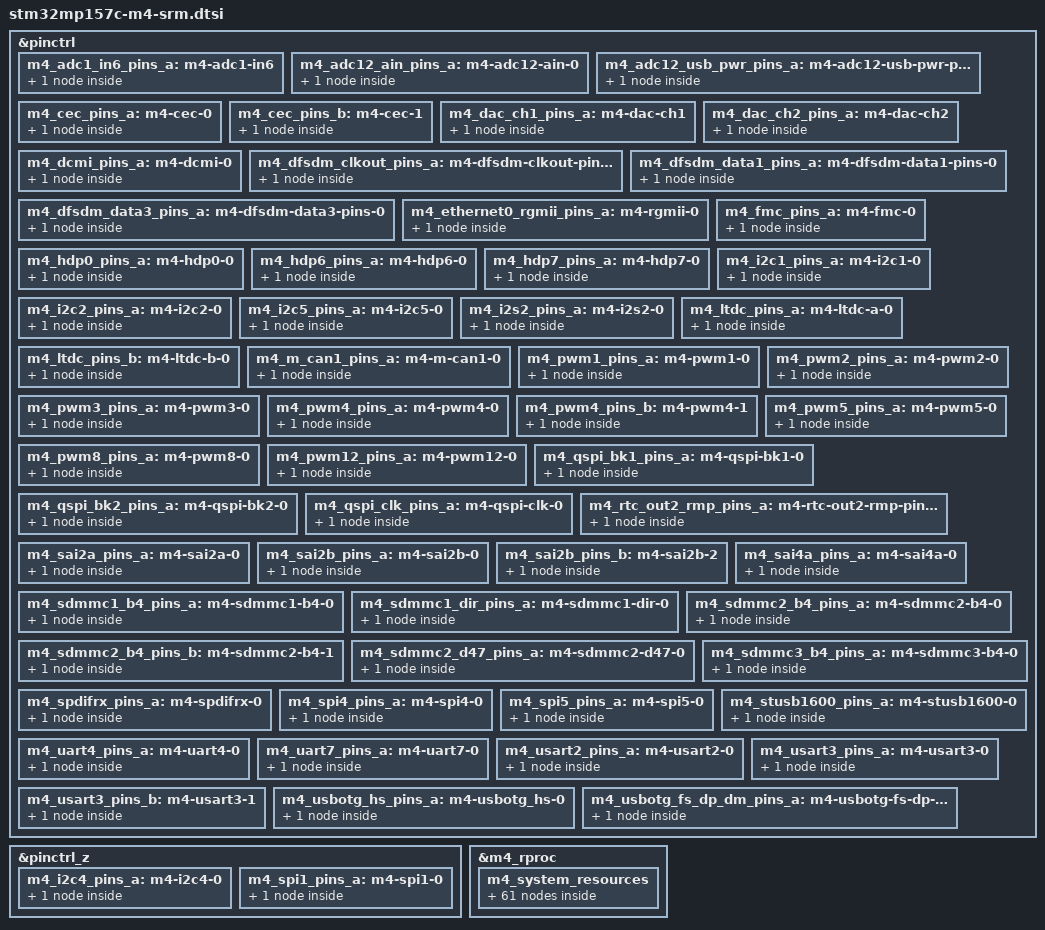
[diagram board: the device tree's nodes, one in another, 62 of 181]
// SPDX-License-Identifier: (GPL-2.0+ OR BSD-3-Clause)
/*
 * Copyright (C) STMicroelectronics 2019 - All Rights Reserved
 * Author: Fabien Dessenne <fabien.dessenne@st.com> for STMicroelectronics.
 */

&pinctrl {
	m4_adc1_in6_pins_a: m4-adc1-in6 {
		pins {
			pinmux = <STM32_PINMUX('F', 12, RSVD)>;
		};
	};

	m4_adc12_ain_pins_a: m4-adc12-ain-0 {
		pins {
			pinmux = <STM32_PINMUX('C', 3, RSVD)>, /* ADC1 in13 */
				 <STM32_PINMUX('F', 12, RSVD)>, /* ADC1 in6 */
				 <STM32_PINMUX('F', 13, RSVD)>, /* ADC2 in2 */
				 <STM32_PINMUX('F', 14, RSVD)>; /* ADC2 in6 */
		};
	};

	m4_adc12_usb_pwr_pins_a: m4-adc12-usb-pwr-pins-0 {
		pins {
			pinmux = <STM32_PINMUX('A', 4, RSVD)>, /* ADC12 in18 */
				 <STM32_PINMUX('A', 5, RSVD)>; /* ADC12 in19 */
		};
	};

	m4_cec_pins_a: m4-cec-0 {
		pins {
			pinmux = <STM32_PINMUX('A', 15, RSVD)>;
		};
	};

	m4_cec_pins_b: m4-cec-1 {
		pins {
			pinmux = <STM32_PINMUX('B', 6, RSVD)>;
		};
	};

	m4_dac_ch1_pins_a: m4-dac-ch1 {
		pins {
			pinmux = <STM32_PINMUX('A', 4, RSVD)>;
		};
	};

	m4_dac_ch2_pins_a: m4-dac-ch2 {
		pins {
			pinmux = <STM32_PINMUX('A', 5, RSVD)>;
		};
	};

	m4_dcmi_pins_a: m4-dcmi-0 {
		pins {
			pinmux = <STM32_PINMUX('H', 8,  RSVD)>,/* DCMI_HSYNC */
				 <STM32_PINMUX('B', 7,  RSVD)>,/* DCMI_VSYNC */
				 <STM32_PINMUX('A', 6,  RSVD)>,/* DCMI_PIXCLK */
				 <STM32_PINMUX('H', 9,  RSVD)>,/* DCMI_D0 */
				 <STM32_PINMUX('H', 10, RSVD)>,/* DCMI_D1 */
				 <STM32_PINMUX('H', 11, RSVD)>,/* DCMI_D2 */
				 <STM32_PINMUX('H', 12, RSVD)>,/* DCMI_D3 */
				 <STM32_PINMUX('H', 14, RSVD)>,/* DCMI_D4 */
				 <STM32_PINMUX('I', 4,  RSVD)>,/* DCMI_D5 */
				 <STM32_PINMUX('B', 8,  RSVD)>,/* DCMI_D6 */
				 <STM32_PINMUX('E', 6,  RSVD)>,/* DCMI_D7 */
				 <STM32_PINMUX('I', 1,  RSVD)>,/* DCMI_D8 */
				 <STM32_PINMUX('H', 7,  RSVD)>,/* DCMI_D9 */
				 <STM32_PINMUX('I', 3,  RSVD)>,/* DCMI_D10 */
				 <STM32_PINMUX('H', 15, RSVD)>;/* DCMI_D11 */
		};
	};

	m4_dfsdm_clkout_pins_a: m4-dfsdm-clkout-pins-0 {
		pins {
			pinmux = <STM32_PINMUX('B', 13, RSVD)>; /* DFSDM_CKOUT */
		};
	};

	m4_dfsdm_data1_pins_a: m4-dfsdm-data1-pins-0 {
		pins {
			pinmux = <STM32_PINMUX('C', 3, RSVD)>; /* DFSDM_DATA1 */
		};
	};

	m4_dfsdm_data3_pins_a: m4-dfsdm-data3-pins-0 {
		pins {
			pinmux = <STM32_PINMUX('F', 13, RSVD)>; /* DFSDM_DATA3 */
		};
	};

	m4_ethernet0_rgmii_pins_a: m4-rgmii-0 {
		pins {
			pinmux = <STM32_PINMUX('G', 5, RSVD)>, /* ETH_RGMII_CLK125 */
				 <STM32_PINMUX('G', 4, RSVD)>, /* ETH_RGMII_GTX_CLK */
				 <STM32_PINMUX('G', 13, RSVD)>, /* ETH_RGMII_TXD0 */
				 <STM32_PINMUX('G', 14, RSVD)>, /* ETH_RGMII_TXD1 */
				 <STM32_PINMUX('C', 2, RSVD)>, /* ETH_RGMII_TXD2 */
				 <STM32_PINMUX('E', 2, RSVD)>, /* ETH_RGMII_TXD3 */
				 <STM32_PINMUX('B', 11, RSVD)>, /* ETH_RGMII_TX_CTL */
				 <STM32_PINMUX('C', 1, RSVD)>, /* ETH_MDC */
				 <STM32_PINMUX('A', 2, RSVD)>, /* ETH_MDIO */
				 <STM32_PINMUX('C', 4, RSVD)>, /* ETH_RGMII_RXD0 */
				 <STM32_PINMUX('C', 5, RSVD)>, /* ETH_RGMII_RXD1 */
				 <STM32_PINMUX('B', 0, RSVD)>, /* ETH_RGMII_RXD2 */
				 <STM32_PINMUX('B', 1, RSVD)>, /* ETH_RGMII_RXD3 */
				 <STM32_PINMUX('A', 1, RSVD)>, /* ETH_RGMII_RX_CLK */
				 <STM32_PINMUX('A', 7, RSVD)>; /* ETH_RGMII_RX_CTL */
		};
	};

	m4_fmc_pins_a: m4-fmc-0 {
		pins {
			pinmux = <STM32_PINMUX('D', 4, RSVD)>, /* FMC_NOE */
				 <STM32_PINMUX('D', 5, RSVD)>, /* FMC_NWE */
				 <STM32_PINMUX('D', 11, RSVD)>, /* FMC_A16_FMC_CLE */
				 <STM32_PINMUX('D', 12, RSVD)>, /* FMC_A17_FMC_ALE */
				 <STM32_PINMUX('D', 14, RSVD)>, /* FMC_D0 */
				 <STM32_PINMUX('D', 15, RSVD)>, /* FMC_D1 */
				 <STM32_PINMUX('D', 0, RSVD)>, /* FMC_D2 */
				 <STM32_PINMUX('D', 1, RSVD)>, /* FMC_D3 */
				 <STM32_PINMUX('E', 7, RSVD)>, /* FMC_D4 */
				 <STM32_PINMUX('E', 8, RSVD)>, /* FMC_D5 */
				 <STM32_PINMUX('E', 9, RSVD)>, /* FMC_D6 */
				 <STM32_PINMUX('E', 10, RSVD)>, /* FMC_D7 */
				 <STM32_PINMUX('G', 9, RSVD)>, /* FMC_NE2_FMC_NCE */
				 <STM32_PINMUX('D', 6, RSVD)>; /* FMC_NWAIT */
		};
	};

	m4_hdp0_pins_a: m4-hdp0-0 {
		pins {
			pinmux = <STM32_PINMUX('I', 12, RSVD)>; /* HDP0 */
		};
	};

	m4_hdp6_pins_a: m4-hdp6-0 {
		pins {
			pinmux = <STM32_PINMUX('K', 5, RSVD)>; /* HDP6 */
		};
	};

	m4_hdp7_pins_a: m4-hdp7-0 {
		pins {
			pinmux = <STM32_PINMUX('K', 6, RSVD)>; /* HDP7 */
		};
	};

	m4_i2c1_pins_a: m4-i2c1-0 {
		pins {
			pinmux = <STM32_PINMUX('D', 12, RSVD)>, /* I2C1_SCL */
				 <STM32_PINMUX('F', 15, RSVD)>; /* I2C1_SDA */
		};
	};

	m4_i2c2_pins_a: m4-i2c2-0 {
		pins {
			pinmux = <STM32_PINMUX('H', 4, RSVD)>, /* I2C2_SCL */
				 <STM32_PINMUX('H', 5, RSVD)>; /* I2C2_SDA */
		};
	};

	m4_i2c5_pins_a: m4-i2c5-0 {
		pins {
			pinmux = <STM32_PINMUX('A', 11, RSVD)>, /* I2C5_SCL */
				 <STM32_PINMUX('A', 12, RSVD)>; /* I2C5_SDA */
		};
	};

	m4_i2s2_pins_a: m4-i2s2-0 {
		pins {
			pinmux = <STM32_PINMUX('I', 3, RSVD)>, /* I2S2_SDO */
				 <STM32_PINMUX('B', 9, RSVD)>, /* I2S2_WS */
				 <STM32_PINMUX('A', 9, RSVD)>; /* I2S2_CK */
		};
	};

	m4_ltdc_pins_a: m4-ltdc-a-0 {
		pins {
			pinmux = <STM32_PINMUX('G',  7, RSVD)>, /* LCD_CLK */
				 <STM32_PINMUX('I', 10, RSVD)>, /* LCD_HSYNC */
				 <STM32_PINMUX('I',  9, RSVD)>, /* LCD_VSYNC */
				 <STM32_PINMUX('F', 10, RSVD)>, /* LCD_DE */
				 <STM32_PINMUX('H',  2, RSVD)>, /* LCD_R0 */
				 <STM32_PINMUX('H',  3, RSVD)>, /* LCD_R1 */
				 <STM32_PINMUX('H',  8, RSVD)>, /* LCD_R2 */
				 <STM32_PINMUX('H',  9, RSVD)>, /* LCD_R3 */
				 <STM32_PINMUX('H', 10, RSVD)>, /* LCD_R4 */
				 <STM32_PINMUX('C',  0, RSVD)>, /* LCD_R5 */
				 <STM32_PINMUX('H', 12, RSVD)>, /* LCD_R6 */
				 <STM32_PINMUX('E', 15, RSVD)>, /* LCD_R7 */
				 <STM32_PINMUX('E',  5, RSVD)>, /* LCD_G0 */
				 <STM32_PINMUX('E',  6, RSVD)>, /* LCD_G1 */
				 <STM32_PINMUX('H', 13, RSVD)>, /* LCD_G2 */
				 <STM32_PINMUX('H', 14, RSVD)>, /* LCD_G3 */
				 <STM32_PINMUX('H', 15, RSVD)>, /* LCD_G4 */
				 <STM32_PINMUX('I',  0, RSVD)>, /* LCD_G5 */
				 <STM32_PINMUX('I',  1, RSVD)>, /* LCD_G6 */
				 <STM32_PINMUX('I',  2, RSVD)>, /* LCD_G7 */
				 <STM32_PINMUX('D',  9, RSVD)>, /* LCD_B0 */
				 <STM32_PINMUX('G', 12, RSVD)>, /* LCD_B1 */
				 <STM32_PINMUX('G', 10, RSVD)>, /* LCD_B2 */
				 <STM32_PINMUX('D', 10, RSVD)>, /* LCD_B3 */
				 <STM32_PINMUX('I',  4, RSVD)>, /* LCD_B4 */
				 <STM32_PINMUX('A',  3, RSVD)>, /* LCD_B5 */
				 <STM32_PINMUX('B',  8, RSVD)>, /* LCD_B6 */
				 <STM32_PINMUX('D',  8, RSVD)>; /* LCD_B7 */
		};
	};

	m4_ltdc_pins_b: m4-ltdc-b-0 {
		pins {
			pinmux = <STM32_PINMUX('I', 14, RSVD)>, /* LCD_CLK */
				 <STM32_PINMUX('I', 12, RSVD)>, /* LCD_HSYNC */
				 <STM32_PINMUX('I', 13, RSVD)>, /* LCD_VSYNC */
				 <STM32_PINMUX('K',  7, RSVD)>, /* LCD_DE */
				 <STM32_PINMUX('I', 15, RSVD)>, /* LCD_R0 */
				 <STM32_PINMUX('J',  0, RSVD)>, /* LCD_R1 */
				 <STM32_PINMUX('J',  1, RSVD)>, /* LCD_R2 */
				 <STM32_PINMUX('J',  2, RSVD)>, /* LCD_R3 */
				 <STM32_PINMUX('J',  3, RSVD)>, /* LCD_R4 */
				 <STM32_PINMUX('J',  4, RSVD)>, /* LCD_R5 */
				 <STM32_PINMUX('J',  5, RSVD)>, /* LCD_R6 */
				 <STM32_PINMUX('J',  6, RSVD)>, /* LCD_R7 */
				 <STM32_PINMUX('J',  7, RSVD)>, /* LCD_G0 */
				 <STM32_PINMUX('J',  8, RSVD)>, /* LCD_G1 */
				 <STM32_PINMUX('J',  9, RSVD)>, /* LCD_G2 */
				 <STM32_PINMUX('J', 10, RSVD)>, /* LCD_G3 */
				 <STM32_PINMUX('J', 11, RSVD)>, /* LCD_G4 */
				 <STM32_PINMUX('K',  0, RSVD)>, /* LCD_G5 */
				 <STM32_PINMUX('K',  1, RSVD)>, /* LCD_G6 */
				 <STM32_PINMUX('K',  2, RSVD)>, /* LCD_G7 */
				 <STM32_PINMUX('J', 12, RSVD)>, /* LCD_B0 */
				 <STM32_PINMUX('J', 13, RSVD)>, /* LCD_B1 */
				 <STM32_PINMUX('J', 14, RSVD)>, /* LCD_B2 */
				 <STM32_PINMUX('J', 15, RSVD)>, /* LCD_B3 */
				 <STM32_PINMUX('K',  3, RSVD)>, /* LCD_B4 */
				 <STM32_PINMUX('K',  4, RSVD)>, /* LCD_B5 */
				 <STM32_PINMUX('K',  5, RSVD)>, /* LCD_B6 */
				 <STM32_PINMUX('K',  6, RSVD)>; /* LCD_B7 */
		};
	};

	m4_m_can1_pins_a: m4-m-can1-0 {
		pins {
			pinmux = <STM32_PINMUX('H', 13, RSVD)>, /* CAN1_TX */
				 <STM32_PINMUX('I', 9, RSVD)>; /* CAN1_RX */
		};
	};

	m4_pwm1_pins_a: m4-pwm1-0 {
		pins {
			pinmux = <STM32_PINMUX('E', 9, RSVD)>, /* TIM1_CH1 */
				 <STM32_PINMUX('E', 11, RSVD)>, /* TIM1_CH2 */
				 <STM32_PINMUX('E', 14, RSVD)>; /* TIM1_CH4 */
		};
	};

	m4_pwm2_pins_a: m4-pwm2-0 {
		pins {
			pinmux = <STM32_PINMUX('A', 3, RSVD)>; /* TIM2_CH4 */
		};
	};

	m4_pwm3_pins_a: m4-pwm3-0 {
		pins {
			pinmux = <STM32_PINMUX('C', 7, RSVD)>; /* TIM3_CH2 */
		};
	};

	m4_pwm4_pins_a: m4-pwm4-0 {
		pins {
			pinmux = <STM32_PINMUX('D', 14, RSVD)>, /* TIM4_CH3 */
				 <STM32_PINMUX('D', 15, RSVD)>; /* TIM4_CH4 */
		};
	};

	m4_pwm4_pins_b: m4-pwm4-1 {
		pins {
			pinmux = <STM32_PINMUX('D', 13, RSVD)>; /* TIM4_CH2 */
		};
	};

	m4_pwm5_pins_a: m4-pwm5-0 {
		pins {
			pinmux = <STM32_PINMUX('H', 11, RSVD)>; /* TIM5_CH2 */
		};
	};

	m4_pwm8_pins_a: m4-pwm8-0 {
		pins {
			pinmux = <STM32_PINMUX('I', 2, RSVD)>; /* TIM8_CH4 */
		};
	};

	m4_pwm12_pins_a: m4-pwm12-0 {
		pins {
			pinmux = <STM32_PINMUX('H', 6, RSVD)>; /* TIM12_CH1 */
		};
	};

	m4_qspi_bk1_pins_a: m4-qspi-bk1-0 {
		pins {
			pinmux = <STM32_PINMUX('F', 8, RSVD)>, /* QSPI_BK1_IO0 */
				 <STM32_PINMUX('F', 9, RSVD)>, /* QSPI_BK1_IO1 */
				 <STM32_PINMUX('F', 7, RSVD)>, /* QSPI_BK1_IO2 */
				 <STM32_PINMUX('F', 6, RSVD)>, /* QSPI_BK1_IO3 */
				 <STM32_PINMUX('B', 6, RSVD)>; /* QSPI_BK1_NCS */
		};
	};

	m4_qspi_bk2_pins_a: m4-qspi-bk2-0 {
		pins {
			pinmux = <STM32_PINMUX('H', 2, RSVD)>, /* QSPI_BK2_IO0 */
				 <STM32_PINMUX('H', 3, RSVD)>, /* QSPI_BK2_IO1 */
				 <STM32_PINMUX('G', 10, RSVD)>, /* QSPI_BK2_IO2 */
				 <STM32_PINMUX('G', 7, RSVD)>, /* QSPI_BK2_IO3 */
				 <STM32_PINMUX('C', 0, RSVD)>; /* QSPI_BK2_NCS */
		};
	};

	m4_qspi_clk_pins_a: m4-qspi-clk-0 {
		pins {
			pinmux = <STM32_PINMUX('F', 10, RSVD)>; /* QSPI_CLK */
		};
	};

	m4_rtc_out2_rmp_pins_a: m4-rtc-out2-rmp-pins-0 {
		pins {
			pinmux = <STM32_PINMUX('I', 8, RSVD)>; /* RTC_OUT2_RMP */
		};
	};

	m4_sai2a_pins_a: m4-sai2a-0 {
		pins {
			pinmux = <STM32_PINMUX('I', 5, RSVD)>, /* SAI2_SCK_A */
				 <STM32_PINMUX('I', 6, RSVD)>, /* SAI2_SD_A */
				 <STM32_PINMUX('I', 7, RSVD)>, /* SAI2_FS_A */
				 <STM32_PINMUX('E', 0, RSVD)>; /* SAI2_MCLK_A */
		};
	};

	m4_sai2b_pins_a: m4-sai2b-0 {
		pins {
			pinmux = <STM32_PINMUX('E', 12, RSVD)>, /* SAI2_SCK_B */
				 <STM32_PINMUX('E', 13, RSVD)>, /* SAI2_FS_B */
				 <STM32_PINMUX('E', 14, RSVD)>, /* SAI2_MCLK_B */
				 <STM32_PINMUX('F', 11, RSVD)>; /* SAI2_SD_B */
		};
	};

	m4_sai2b_pins_b: m4-sai2b-2 {
		pins {
			pinmux = <STM32_PINMUX('F', 11, RSVD)>; /* SAI2_SD_B */
		};
	};

	m4_sai4a_pins_a: m4-sai4a-0 {
		pins {
			pinmux = <STM32_PINMUX('B', 5, RSVD)>; /* SAI4_SD_A */
		};
	};

	m4_sdmmc1_b4_pins_a: m4-sdmmc1-b4-0 {
		pins {
			pinmux = <STM32_PINMUX('C', 8, RSVD)>, /* SDMMC1_D0 */
				 <STM32_PINMUX('C', 9, RSVD)>, /* SDMMC1_D1 */
				 <STM32_PINMUX('C', 10, RSVD)>, /* SDMMC1_D2 */
				 <STM32_PINMUX('C', 11, RSVD)>, /* SDMMC1_D3 */
				 <STM32_PINMUX('D', 2, RSVD)>, /* SDMMC1_CMD */
				 <STM32_PINMUX('C', 12, RSVD)>; /* SDMMC1_CK */
		};
	};

	m4_sdmmc1_dir_pins_a: m4-sdmmc1-dir-0 {
		pins {
			pinmux = <STM32_PINMUX('F', 2, RSVD)>, /* SDMMC1_D0DIR */
				 <STM32_PINMUX('C', 7, RSVD)>, /* SDMMC1_D123DIR */
				 <STM32_PINMUX('B', 9, RSVD)>, /* SDMMC1_CDIR */
				 <STM32_PINMUX('E', 4, RSVD)>; /* SDMMC1_CKIN */
		};
	};

	m4_sdmmc2_b4_pins_a: m4-sdmmc2-b4-0 {
		pins {
			pinmux = <STM32_PINMUX('B', 14, RSVD)>, /* SDMMC2_D0 */
				 <STM32_PINMUX('B', 15, RSVD)>, /* SDMMC2_D1 */
				 <STM32_PINMUX('B', 3, RSVD)>, /* SDMMC2_D2 */
				 <STM32_PINMUX('B', 4, RSVD)>, /* SDMMC2_D3 */
				 <STM32_PINMUX('G', 6, RSVD)>, /* SDMMC2_CMD */
				 <STM32_PINMUX('E', 3, RSVD)>; /* SDMMC2_CK */
		};
	};

	m4_sdmmc2_b4_pins_b: m4-sdmmc2-b4-1 {
		pins {
			pinmux = <STM32_PINMUX('B', 14, RSVD)>, /* SDMMC2_D0 */
				 <STM32_PINMUX('B', 15, RSVD)>, /* SDMMC2_D1 */
				 <STM32_PINMUX('B', 3, RSVD)>, /* SDMMC2_D2 */
				 <STM32_PINMUX('B', 4, RSVD)>, /* SDMMC2_D3 */
				 <STM32_PINMUX('G', 6, RSVD)>, /* SDMMC2_CMD */
				 <STM32_PINMUX('E', 3, RSVD)>; /* SDMMC2_CK */
		};
	};

	m4_sdmmc2_d47_pins_a: m4-sdmmc2-d47-0 {
		pins {
			pinmux = <STM32_PINMUX('A', 8, RSVD)>, /* SDMMC2_D4 */
				 <STM32_PINMUX('A', 9, RSVD)>, /* SDMMC2_D5 */
				 <STM32_PINMUX('E', 5, RSVD)>, /* SDMMC2_D6 */
				 <STM32_PINMUX('D', 3, RSVD)>; /* SDMMC2_D7 */
		};
	};

	m4_sdmmc3_b4_pins_a: m4-sdmmc3-b4-0 {
		pins {
			pinmux = <STM32_PINMUX('F', 0, RSVD)>, /* SDMMC3_D0 */
				 <STM32_PINMUX('F', 4, RSVD)>, /* SDMMC3_D1 */
				 <STM32_PINMUX('F', 5, RSVD)>, /* SDMMC3_D2 */
				 <STM32_PINMUX('D', 7, RSVD)>, /* SDMMC3_D3 */
				 <STM32_PINMUX('F', 1, RSVD)>, /* SDMMC3_CMD */
				 <STM32_PINMUX('G', 15, RSVD)>; /* SDMMC3_CK */
		};
	};

	m4_spdifrx_pins_a: m4-spdifrx-0 {
		pins {
			pinmux = <STM32_PINMUX('G', 12, RSVD)>; /* SPDIF_IN1 */
		};
	};

	m4_spi4_pins_a: m4-spi4-0 {
		pins {
			pinmux = <STM32_PINMUX('E', 12, RSVD)>, /* SPI4_SCK */
				 <STM32_PINMUX('E', 14, RSVD)>, /* SPI4_MOSI */
				 <STM32_PINMUX('E', 13, RSVD)>; /* SPI4_MISO */
		};
	};

	m4_spi5_pins_a: m4-spi5-0 {
		pins {
			pinmux = <STM32_PINMUX('F', 7, RSVD)>, /* SPI5_SCK */
				 <STM32_PINMUX('F', 9, RSVD)>, /* SPI5_MOSI */
				 <STM32_PINMUX('F', 8, RSVD)>; /* SPI5_MISO */
		};
	};

	m4_stusb1600_pins_a: m4-stusb1600-0 {
		pins {
			pinmux = <STM32_PINMUX('I', 11, RSVD)>;
		};
	};

	m4_uart4_pins_a: m4-uart4-0 {
		pins {
			pinmux = <STM32_PINMUX('G', 11, RSVD)>, /* UART4_TX */
				 <STM32_PINMUX('B', 2, RSVD)>; /* UART4_RX */
		};
	};

	m4_uart7_pins_a: m4-uart7-0 {
		pins {
			pinmux = <STM32_PINMUX('E', 8, RSVD)>, /* USART7_TX */
				 <STM32_PINMUX('E', 7, RSVD)>; /* USART7_RX */
		};
	};

	m4_usart2_pins_a: m4-usart2-0 {
		pins {
			pinmux = <STM32_PINMUX('D', 5, RSVD)>, /* USART2_TX */
				 <STM32_PINMUX('D', 4, RSVD)>, /* USART2_RTS */
				 <STM32_PINMUX('D', 6, RSVD)>, /* USART2_RX */
				 <STM32_PINMUX('D', 3, RSVD)>; /* USART2_CTS_NSS */
		};
	};

	m4_usart3_pins_a: m4-usart3-0 {
		pins {
			pinmux = <STM32_PINMUX('B', 10, RSVD)>, /* USART3_TX */
				 <STM32_PINMUX('G', 8, RSVD)>, /* USART3_RTS */
				 <STM32_PINMUX('B', 12, RSVD)>, /* USART3_RX */
				 <STM32_PINMUX('I', 10, RSVD)>; /* USART3_CTS_NSS */
		};
	};

	m4_usart3_pins_b: m4-usart3-1 {
		pins {
			pinmux = <STM32_PINMUX('B', 10, RSVD)>, /* USART3_TX */
				 <STM32_PINMUX('G', 8, RSVD)>, /* USART3_RTS */
				 <STM32_PINMUX('B', 12, RSVD)>, /* USART3_RX */
				 <STM32_PINMUX('B', 13, RSVD)>; /* USART3_CTS_NSS */
		};
	};

	m4_usbotg_hs_pins_a: m4-usbotg_hs-0 {
		pins {
			pinmux = <STM32_PINMUX('A', 10, RSVD)>; /* OTG_ID */
		};
	};

	m4_usbotg_fs_dp_dm_pins_a: m4-usbotg-fs-dp-dm-0 {
		pins {
			pinmux = <STM32_PINMUX('A', 11, RSVD)>, /* OTG_FS_DM */
				 <STM32_PINMUX('A', 12, RSVD)>; /* OTG_FS_DP */
		};
	};
};

&pinctrl_z {
	m4_i2c4_pins_a: m4-i2c4-0 {
		pins {
			pinmux = <STM32_PINMUX('Z', 4, AF6)>, /* I2C4_SCL */
				 <STM32_PINMUX('Z', 5, AF6)>; /* I2C4_SDA */
		};
	};

	m4_spi1_pins_a: m4-spi1-0 {
		pins {
			pinmux = <STM32_PINMUX('Z', 0, AF5)>, /* SPI1_SCK */
				 <STM32_PINMUX('Z', 2, AF5)>, /* SPI1_MOSI */
				 <STM32_PINMUX('Z', 1, AF5)>; /* SPI1_MISO */
		};
	};
};

&m4_rproc {
	m4_system_resources {
		#address-cells = <1>;
		#size-cells = <0>;

		m4_timers2: timer@40000000 {
			compatible = "rproc-srm-dev";
			reg = <0x40000000>;
			clocks = <&rcc TIM2_K>;
			clock-names = "int";
			status = "disabled";
		};
		m4_timers3: timer@40001000 {
			compatible = "rproc-srm-dev";
			reg = <0x40001000>;
			clocks = <&rcc TIM3_K>;
			clock-names = "int";
			status = "disabled";
		};
		m4_timers4: timer@40002000 {
			compatible = "rproc-srm-dev";
			reg = <0x40002000>;
			clocks = <&rcc TIM4_K>;
			clock-names = "int";
			status = "disabled";
		};
		m4_timers5: timer@40003000 {
			compatible = "rproc-srm-dev";
			reg = <0x40003000>;
			clocks = <&rcc TIM5_K>;
			clock-names = "int";
			status = "disabled";
		};
		m4_timers6: timer@40004000 {
			compatible = "rproc-srm-dev";
			reg = <0x40004000>;
			clocks = <&rcc TIM6_K>;
			clock-names = "int";
			status = "disabled";
		};
		m4_timers7: timer@40005000 {
			compatible = "rproc-srm-dev";
			reg = <0x40005000>;
			clocks = <&rcc TIM7_K>;
			clock-names = "int";
			status = "disabled";
		};
		m4_timers12: timer@40006000 {
			compatible = "rproc-srm-dev";
			reg = <0x40006000>;
			clocks = <&rcc TIM12_K>;
			clock-names = "int";
			status = "disabled";
		};
		m4_timers13: timer@40007000 {
			compatible = "rproc-srm-dev";
			reg = <0x40007000>;
			clocks = <&rcc TIM13_K>;
			clock-names = "int";
			status = "disabled";
		};
		m4_timers14: timer@40008000 {
			compatible = "rproc-srm-dev";
			reg = <0x40008000>;
			clocks = <&rcc TIM14_K>;
			clock-names = "int";
			status = "disabled";
		};
		m4_lptimer1: timer@40009000 {
			compatible = "rproc-srm-dev";
			reg = <0x40009000>;
			clocks = <&rcc LPTIM1_K>;
			clock-names = "mux";
			status = "disabled";
		};
		m4_spi2: spi@4000b000 {
			compatible = "rproc-srm-dev";
			reg = <0x4000b000>;
			clocks = <&rcc SPI2_K>;
			status = "disabled";
		};
		m4_i2s2: audio-controller@4000b000 {
			compatible = "rproc-srm-dev";
			reg = <0x4000b000>;
			status = "disabled";
		};
		m4_spi3: spi@4000c000 {
			compatible = "rproc-srm-dev";
			reg = <0x4000c000>;
			clocks = <&rcc SPI3_K>;
			status = "disabled";
		};
		m4_i2s3: audio-controller@4000c000 {
			compatible = "rproc-srm-dev";
			reg = <0x4000c000>;
			status = "disabled";
		};
		m4_spdifrx: audio-controller@4000d000 {
			compatible = "rproc-srm-dev";
			reg = <0x4000d000>;
			clocks = <&rcc SPDIF_K>;
			clock-names = "kclk";
			status = "disabled";
		};
		m4_usart2: serial@4000e000 {
			compatible = "rproc-srm-dev";
			reg = <0x4000e000>;
			interrupt-parent = <&exti>;
			interrupts = <27 1>;
			clocks = <&rcc USART2_K>;
			status = "disabled";
		};
		m4_usart3: serial@4000f000 {
			compatible = "rproc-srm-dev";
			reg = <0x4000f000>;
			interrupt-parent = <&exti>;
			interrupts = <28 1>;
			clocks = <&rcc USART3_K>;
			status = "disabled";
		};
		m4_uart4: serial@40010000 {
			compatible = "rproc-srm-dev";
			reg = <0x40010000>;
			interrupt-parent = <&exti>;
			interrupts = <30 1>;
			clocks = <&rcc UART4_K>;
			status = "disabled";
		};
		m4_uart5: serial@40011000 {
			compatible = "rproc-srm-dev";
			reg = <0x40011000>;
			interrupt-parent = <&exti>;
			interrupts = <31 1>;
			clocks = <&rcc UART5_K>;
			status = "disabled";
		};
		m4_i2c1: i2c@40012000 {
			compatible = "rproc-srm-dev";
			reg = <0x40012000>;
			interrupt-parent = <&exti>;
			interrupts = <21 1>;
			clocks = <&rcc I2C1_K>;
			status = "disabled";
		};
		m4_i2c2: i2c@40013000 {
			compatible = "rproc-srm-dev";
			reg = <0x40013000>;
			interrupt-parent = <&exti>;
			interrupts = <22 1>;
			clocks = <&rcc I2C2_K>;
			status = "disabled";
		};
		m4_i2c3: i2c@40014000 {
			compatible = "rproc-srm-dev";
			reg = <0x40014000>;
			interrupt-parent = <&exti>;
			interrupts = <23 1>;
			clocks = <&rcc I2C3_K>;
			status = "disabled";
		};
		m4_i2c5: i2c@40015000 {
			compatible = "rproc-srm-dev";
			reg = <0x40015000>;
			interrupt-parent = <&exti>;
			interrupts = <25 1>;
			clocks = <&rcc I2C5_K>;
			status = "disabled";
		};
		m4_cec: cec@40016000 {
			compatible = "rproc-srm-dev";
			reg = <0x40016000>;
			interrupt-parent = <&exti>;
			interrupts = <69 1>;
			clocks = <&rcc CEC_K>, <&rcc CK_LSE>;
			clock-names = "cec", "hdmi-cec";
			status = "disabled";
		};
		m4_dac: dac@40017000 {
			compatible = "rproc-srm-dev";
			reg = <0x40017000>;
			clocks = <&rcc DAC12>;
			clock-names = "pclk";
			status = "disabled";
		};
		m4_uart7: serial@40018000 {
			compatible = "rproc-srm-dev";
			reg = <0x40018000>;
			interrupt-parent = <&exti>;
			interrupts = <32 1>;
			clocks = <&rcc UART7_K>;
			status = "disabled";
		};
		m4_uart8: serial@40019000 {
			compatible = "rproc-srm-dev";
			reg = <0x40019000>;
			interrupt-parent = <&exti>;
			interrupts = <33 1>;
			clocks = <&rcc UART8_K>;
			status = "disabled";
		};
		m4_timers1: timer@44000000 {
			compatible = "rproc-srm-dev";
			reg = <0x44000000>;
			clocks = <&rcc TIM1_K>;
			clock-names = "int";
			status = "disabled";
		};
		m4_timers8: timer@44001000 {
			compatible = "rproc-srm-dev";
			reg = <0x44001000>;
			clocks = <&rcc TIM8_K>;
			clock-names = "int";
			status = "disabled";
		};
		m4_usart6: serial@44003000 {
			compatible = "rproc-srm-dev";
			reg = <0x44003000>;
			interrupt-parent = <&exti>;
			interrupts = <29 1>;
			clocks = <&rcc USART6_K>;
			status = "disabled";
		};
		m4_spi1: spi@44004000 {
			compatible = "rproc-srm-dev";
			reg = <0x44004000>;
			clocks = <&rcc SPI1_K>;
			status = "disabled";
		};
		m4_i2s1: audio-controller@44004000 {
			compatible = "rproc-srm-dev";
			reg = <0x44004000>;
			status = "disabled";
		};
		m4_spi4: spi@44005000 {
			compatible = "rproc-srm-dev";
			reg = <0x44005000>;
			clocks = <&rcc SPI4_K>;
			status = "disabled";
		};
		m4_timers15: timer@44006000 {
			compatible = "rproc-srm-dev";
			reg = <0x44006000>;
			clocks = <&rcc TIM15_K>;
			clock-names = "int";
			status = "disabled";
		};
		m4_timers16: timer@44007000 {
			compatible = "rproc-srm-dev";
			reg = <0x44007000>;
			clocks = <&rcc TIM16_K>;
			clock-names = "int";
			status = "disabled";
		};
		m4_timers17: timer@44008000 {
			compatible = "rproc-srm-dev";
			reg = <0x44008000>;
			clocks = <&rcc TIM17_K>;
			clock-names = "int";
			status = "disabled";
		};
		m4_spi5: spi@44009000 {
			compatible = "rproc-srm-dev";
			reg = <0x44009000>;
			clocks = <&rcc SPI5_K>;
			status = "disabled";
		};
		m4_sai1: sai@4400a000 {
			compatible = "rproc-srm-dev";
			reg = <0x4400a000>;
			clocks = <&rcc SAI1_K>;
			clock-names = "sai_ck";
			status = "disabled";
		};
		m4_sai2: sai@4400b000 {
			compatible = "rproc-srm-dev";
			reg = <0x4400b000>;
			clocks = <&rcc SAI2_K>;
			clock-names = "sai_ck";
			status = "disabled";
		};
		m4_sai3: sai@4400c000 {
			compatible = "rproc-srm-dev";
			reg = <0x4400c000>;
			clocks = <&rcc SAI3_K>;
			clock-names = "sai_ck";
			status = "disabled";
		};
		m4_dfsdm: dfsdm@4400d000 {
			compatible = "rproc-srm-dev";
			reg = <0x4400d000>;
			clocks = <&rcc DFSDM_K>;
			clock-names = "dfsdm";
			status = "disabled";
		};
		m4_m_can1: can@4400e000 {
			compatible = "rproc-srm-dev";
			reg = <0x4400e000>, <0x44011000>;
			clocks = <&rcc FDCAN>, <&rcc FDCAN_K>;
			clock-names = "hclk", "cclk";
			status = "disabled";
		};
		m4_m_can2: can@4400f000 {
			compatible = "rproc-srm-dev";
			reg = <0x4400f000>, <0x44011000>;
			clocks = <&rcc FDCAN>, <&rcc FDCAN_K>;
			clock-names = "hclk", "cclk";
			status = "disabled";
		};
		m4_dma1: dma@48000000 {
			compatible = "rproc-srm-dev";
			reg = <0x48000000>;
			clocks = <&rcc DMA1>;
			status = "disabled";
		};
		m4_dma2: dma@48001000 {
			compatible = "rproc-srm-dev";
			reg = <0x48001000>;
			clocks = <&rcc DMA2>;
			status = "disabled";
		};
		m4_dmamux1: dma-router@48002000 {
			compatible = "rproc-srm-dev";
			reg = <0x48002000>;
			clocks = <&rcc DMAMUX>;
			status = "disabled";
		};
		m4_adc: adc@48003000 {
			compatible = "rproc-srm-dev";
			reg = <0x48003000>;
			clocks = <&rcc ADC12>, <&rcc ADC12_K>;
			clock-names = "bus", "adc";
			status = "disabled";
		};
		m4_sdmmc3: sdmmc@48004000 {
			compatible = "rproc-srm-dev";
			reg = <0x48004000>, <0x48005000>;
			clocks = <&rcc SDMMC3_K>;
			status = "disabled";
		};
		m4_usbotg_hs: usb-otg@49000000 {
			compatible = "rproc-srm-dev";
			reg = <0x49000000>;
			clocks = <&rcc USBO_K>;
			clock-names = "otg";
			status = "disabled";
		};
		m4_hash2: hash@4c002000 {
			compatible = "rproc-srm-dev";
			reg = <0x4c002000>;
			clocks = <&rcc HASH2>;
			status = "disabled";
		};
		m4_rng2: rng@4c003000 {
			compatible = "rproc-srm-dev";
			reg = <0x4c003000>;
			clocks = <&rcc RNG2_K>;
			status = "disabled";
		};
		m4_crc2: crc@4c004000 {
			compatible = "rproc-srm-dev";
			reg = <0x4c004000>;
			clocks = <&rcc CRC2>;
			status = "disabled";
		};
		m4_cryp2: cryp@4c005000 {
			compatible = "rproc-srm-dev";
			reg = <0x4c005000>;
			clocks = <&rcc CRYP2>;
			status = "disabled";
		};
		m4_dcmi: dcmi@4c006000 {
			compatible = "rproc-srm-dev";
			reg = <0x4c006000>;
			clocks = <&rcc DCMI>;
			clock-names = "mclk";
			status = "disabled";
		};
		m4_lptimer2: timer@50021000 {
			compatible = "rproc-srm-dev";
			reg = <0x50021000>;
			clocks = <&rcc LPTIM2_K>;
			clock-names = "mux";
			status = "disabled";
		};
		m4_lptimer3: timer@50022000 {
			compatible = "rproc-srm-dev";
			reg = <0x50022000>;
			clocks = <&rcc LPTIM3_K>;
			clock-names = "mux";
			status = "disabled";
		};
		m4_lptimer4: timer@50023000 {
			compatible = "rproc-srm-dev";
			reg = <0x50023000>;
			clocks = <&rcc LPTIM4_K>;
			clock-names = "mux";
			status = "disabled";
		};
		m4_lptimer5: timer@50024000 {
			compatible = "rproc-srm-dev";
			reg = <0x50024000>;
			clocks = <&rcc LPTIM5_K>;
			clock-names = "mux";
			status = "disabled";
		};
		m4_sai4: sai@50027000 {
			compatible = "rproc-srm-dev";
			reg = <0x50027000>;
			clocks = <&rcc SAI4_K>;
			clock-names = "sai_ck";
			status = "disabled";
		};
		m4_qspi: qspi@58003000 {
			compatible = "rproc-srm-dev";
			reg = <0x58003000>, <0x70000000>;
			clocks = <&rcc QSPI_K>;
			status = "disabled";
		};
		m4_ethernet0: ethernet@5800a000 {
			compatible = "rproc-srm-dev";
			reg = <0x5800a000>;
			clock-names = "stmmaceth",
				      "mac-clk-tx",
				      "mac-clk-rx",
				      "ethstp",
				      "syscfg-clk";
			clocks = <&rcc ETHMAC>,
				 <&rcc ETHTX>,
				 <&rcc ETHRX>,
				 <&rcc ETHSTP>,
				 <&rcc SYSCFG>;
			status = "disabled";
		};
	};
};

